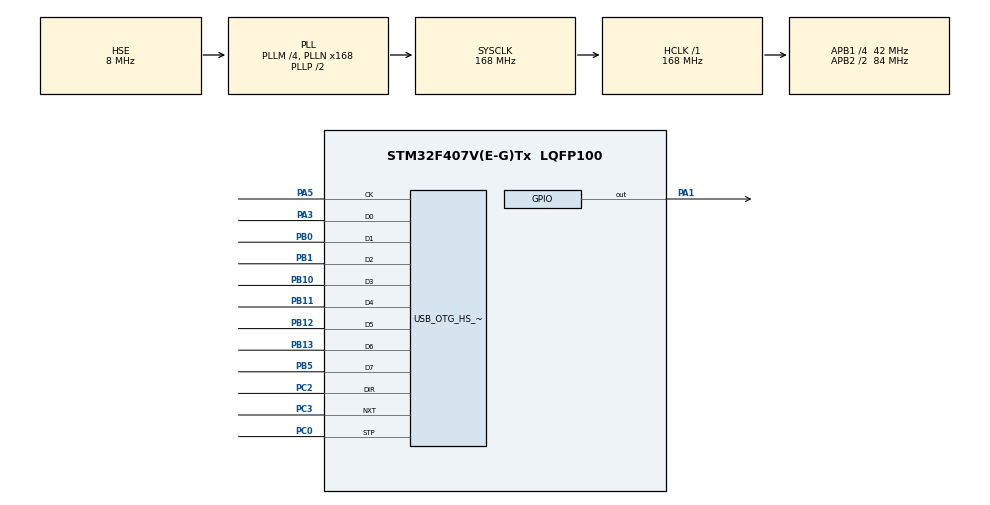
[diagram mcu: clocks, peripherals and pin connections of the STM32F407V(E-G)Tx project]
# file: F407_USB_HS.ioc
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FREERTOS.BinarySemaphores01=usbTxSemaphore,Dynamic,NULL
FREERTOS.INCLUDE_vTaskDelayUntil=1
FREERTOS.Tasks01=defaultTask,0,256,StartDefaultTask,Default,NULL,Dynamic,NULL,NULL;ledTask,-3,128,LEDTask,Default,NULL,Dynamic,NULL,NULL
FREERTOS.configTOTAL_HEAP_SIZE=10240
Mcu.Family=STM32F4
Mcu.Name=STM32F407V(E-G)Tx
Mcu.Package=LQFP100
NVIC.OTG_HS_IRQn=true\:5\:0\:false\:false\:true\:true\:false\:true\:true
NVIC.PriorityGroup=NVIC_PRIORITYGROUP_4
NVIC.TIM8_TRG_COM_TIM14_IRQn=true\:15\:0\:false\:false\:true\:false\:false\:true\:true
NVIC.TimeBase=TIM8_TRG_COM_TIM14_IRQn
NVIC.TimeBaseIP=TIM14
PA1.Signal=GPIO_Output
PA13.Mode=Serial_Wire
PA13.Signal=SYS_JTMS-SWDIO
PA14.Mode=Serial_Wire
PA14.Signal=SYS_JTCK-SWCLK
PA3.Mode=Device_HS
PA3.Signal=USB_OTG_HS_ULPI_D0
PA5.Mode=Device_HS
PA5.Signal=USB_OTG_HS_ULPI_CK
PB0.Mode=Device_HS
PB0.Signal=USB_OTG_HS_ULPI_D1
PB1.Mode=Device_HS
PB1.Signal=USB_OTG_HS_ULPI_D2
PB10.Mode=Device_HS
PB10.Signal=USB_OTG_HS_ULPI_D3
PB11.Mode=Device_HS
PB11.Signal=USB_OTG_HS_ULPI_D4
PB12.Mode=Device_HS
PB12.Signal=USB_OTG_HS_ULPI_D5
PB13.Mode=Device_HS
PB13.Signal=USB_OTG_HS_ULPI_D6
PB5.Mode=Device_HS
PB5.Signal=USB_OTG_HS_ULPI_D7
PC0.Mode=Device_HS
PC0.Signal=USB_OTG_HS_ULPI_STP
PC2.Mode=Device_HS
PC2.Signal=USB_OTG_HS_ULPI_DIR
PC3.Mode=Device_HS
PC3.Signal=USB_OTG_HS_ULPI_NXT
PH0-OSC_IN.Mode=HSE-External-Oscillator
PH0-OSC_IN.Signal=RCC_OSC_IN
PH1-OSC_OUT.Mode=HSE-External-Oscillator
PH1-OSC_OUT.Signal=RCC_OSC_OUT
ProjectManager.HeapSize=0x100
ProjectManager.StackSize=0x1000
ProjectManager.TargetToolchain=MDK-ARM V5.32
RCC.48MHZClocksFreq_Value=48000000
RCC.AHBFreq_Value=168000000
RCC.APB1CLKDivider=RCC_HCLK_DIV4
RCC.APB1Freq_Value=42000000
RCC.APB1TimFreq_Value=84000000
RCC.APB2CLKDivider=RCC_HCLK_DIV2
RCC.APB2Freq_Value=84000000
RCC.APB2TimFreq_Value=168000000
RCC.CortexFreq_Value=168000000
RCC.HCLKFreq_Value=168000000
RCC.HSE_VALUE=8000000
RCC.HSI_VALUE=16000000
RCC.LSE_VALUE=32768
RCC.PLLM=4
RCC.PLLN=168
RCC.PLLQ=7
RCC.PLLSourceVirtual=RCC_PLLSOURCE_HSE
RCC.SYSCLKFreq_VALUE=168000000
RCC.SYSCLKSource=RCC_SYSCLKSOURCE_PLLCLK
RCC.VCOOutputFreq_Value=336000000
USB_DEVICE.CLASS_NAME_HS=CDC
USB_DEVICE.VirtualMode-CDC_HS=Cdc
USB_DEVICE.VirtualModeHS=Cdc_HS
USB_OTG_HS.VirtualMode-Device_HS=Device_HS
VP_FREERTOS_VS_CMSIS_V1.Mode=CMSIS_V1
VP_SYS_VS_tim14.Mode=TIM14
VP_USB_DEVICE_VS_USB_DEVICE_CDC_HS.Mode=CDC_HS
board=custom

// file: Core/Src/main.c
/* USER CODE BEGIN Header */
/**
  ******************************************************************************
  * @file           : main.c
  * @brief          : Main program body
  ******************************************************************************
  * @attention
  *
  * Copyright (c) 2025 STMicroelectronics.
  * All rights reserved.
  *
  * This software is licensed under terms that can be found in the LICENSE file
  * in the root directory of this software component.
  * If no LICENSE file comes with this software, it is provided AS-IS.
  *
  ******************************************************************************
  */
/* USER CODE END Header */
#include "main.h"
#include "cmsis_os.h"
#include "usb_device.h"
#include "gpio.h"

void SystemClock_Config(void);
void MX_FREERTOS_Init(void);

int main(void)
{

  /* MCU Configuration--------------------------------------------------------*/

  /* Reset of all peripherals, Initializes the Flash interface and the Systick. */
  HAL_Init();

  /* Configure the system clock */
  SystemClock_Config();

  /* Initialize all configured peripherals */
  MX_GPIO_Init();

  /* Call init function for freertos objects (in freertos.c) */
  MX_FREERTOS_Init();

  /* Start scheduler */
  osKernelStart();

  /* We should never get here as control is now taken by the scheduler */
  /* Infinite loop */
  while (1)
  {

  }
}

void SystemClock_Config(void)
{
  RCC_OscInitTypeDef RCC_OscInitStruct = {0};
  RCC_ClkInitTypeDef RCC_ClkInitStruct = {0};

  /** Configure the main internal regulator output voltage
  */
  __HAL_RCC_PWR_CLK_ENABLE();
  __HAL_PWR_VOLTAGESCALING_CONFIG(PWR_REGULATOR_VOLTAGE_SCALE1);

  /** Initializes the RCC Oscillators according to the specified parameters
  * in the RCC_OscInitTypeDef structure.
  */
  RCC_OscInitStruct.OscillatorType = RCC_OSCILLATORTYPE_HSE;
  RCC_OscInitStruct.HSEState = RCC_HSE_ON;
  RCC_OscInitStruct.PLL.PLLState = RCC_PLL_ON;
  RCC_OscInitStruct.PLL.PLLSource = RCC_PLLSOURCE_HSE;
  RCC_OscInitStruct.PLL.PLLM = 4;
  RCC_OscInitStruct.PLL.PLLN = 168;
  RCC_OscInitStruct.PLL.PLLP = RCC_PLLP_DIV2;
  RCC_OscInitStruct.PLL.PLLQ = 7;
  if (HAL_RCC_OscConfig(&RCC_OscInitStruct) != HAL_OK)
  {
    Error_Handler();
  }

  /** Initializes the CPU, AHB and APB buses clocks
  */
  RCC_ClkInitStruct.ClockType = RCC_CLOCKTYPE_HCLK|RCC_CLOCKTYPE_SYSCLK
                              |RCC_CLOCKTYPE_PCLK1|RCC_CLOCKTYPE_PCLK2;
  RCC_ClkInitStruct.SYSCLKSource = RCC_SYSCLKSOURCE_PLLCLK;
  RCC_ClkInitStruct.AHBCLKDivider = RCC_SYSCLK_DIV1;
  RCC_ClkInitStruct.APB1CLKDivider = RCC_HCLK_DIV4;
  RCC_ClkInitStruct.APB2CLKDivider = RCC_HCLK_DIV2;

  if (HAL_RCC_ClockConfig(&RCC_ClkInitStruct, FLASH_LATENCY_5) != HAL_OK)
  {
    Error_Handler();
  }
}

void HAL_TIM_PeriodElapsedCallback(TIM_HandleTypeDef *htim)
{
  if (htim->Instance == TIM14) {
    HAL_IncTick();
  }
}

void Error_Handler(void)
{
  __disable_irq();
  while (1)
  {
  }
}

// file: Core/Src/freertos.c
/* USER CODE BEGIN Header */
/**
  ******************************************************************************
  * File Name          : freertos.c
  * Description        : Code for freertos applications
  ******************************************************************************
  * @attention
  *
  * Copyright (c) 2025 STMicroelectronics.
  * All rights reserved.
  *
  * This software is licensed under terms that can be found in the LICENSE file
  * in the root directory of this software component.
  * If no LICENSE file comes with this software, it is provided AS-IS.
  *
  ******************************************************************************
  */
/* USER CODE END Header */

#include "FreeRTOS.h"
#include "task.h"
#include "main.h"
#include "cmsis_os.h"

/* USER CODE BEGIN Includes */
#include "usbd_cdc_if.h"
/* USER CODE END Includes */

osThreadId defaultTaskHandle;
osThreadId ledTaskHandle;
osSemaphoreId usbTxSemaphoreHandle;

void StartDefaultTask(void const * argument);
void LEDTask(void const * argument);

extern void MX_USB_DEVICE_Init(void);
void MX_FREERTOS_Init(void); /* (MISRA C 2004 rule 8.1) */

/* GetIdleTaskMemory prototype (linked to static allocation support) */
void vApplicationGetIdleTaskMemory( StaticTask_t **ppxIdleTaskTCBBuffer, StackType_t **ppxIdleTaskStackBuffer, uint32_t *pulIdleTaskStackSize );

/* USER CODE BEGIN GET_IDLE_TASK_MEMORY */
static StaticTask_t xIdleTaskTCBBuffer;
static StackType_t xIdleStack[configMINIMAL_STACK_SIZE];

void vApplicationGetIdleTaskMemory( StaticTask_t **ppxIdleTaskTCBBuffer, StackType_t **ppxIdleTaskStackBuffer, uint32_t *pulIdleTaskStackSize )
{
  *ppxIdleTaskTCBBuffer = &xIdleTaskTCBBuffer;
  *ppxIdleTaskStackBuffer = &xIdleStack[0];
  *pulIdleTaskStackSize = configMINIMAL_STACK_SIZE;
  /* place for user code */
}
/* USER CODE END GET_IDLE_TASK_MEMORY */

void MX_FREERTOS_Init(void) {

  /* Create the semaphores(s) */
  /* definition and creation of usbTxSemaphore */
  osSemaphoreDef(usbTxSemaphore);
  usbTxSemaphoreHandle = osSemaphoreCreate(osSemaphore(usbTxSemaphore), 1);

  /* Create the thread(s) */
  /* definition and creation of defaultTask */
  osThreadDef(defaultTask, StartDefaultTask, osPriorityNormal, 0, 256);
  defaultTaskHandle = osThreadCreate(osThread(defaultTask), NULL);

  /* definition and creation of ledTask */
  osThreadDef(ledTask, LEDTask, osPriorityIdle, 0, 128);
  ledTaskHandle = osThreadCreate(osThread(ledTask), NULL);

}

/* USER CODE BEGIN Header_StartDefaultTask */
unsigned char test_buf[]="hello world\r\n";
unsigned char speed_test[10240];
/**
  * @brief  Function implementing the defaultTask thread.
  * @param  argument: Not used
  * @retval None
  */
/* USER CODE END Header_StartDefaultTask */
void StartDefaultTask(void const * argument)
{
  /* init code for USB_DEVICE */
  MX_USB_DEVICE_Init();
  /* USER CODE BEGIN StartDefaultTask */
	USBD_StatusTypeDef USB_TX_Status = USBD_OK;

	for(uint16_t i=0;i<10240;i++)
	{
		speed_test[i]=i;
	}
  /* Infinite loop */
	for(;;)
	{
//		do
//		{
//			USB_TX_Status = CDC_Transmit_HS(speed_test,sizeof(speed_test));
//		}
//		while(USB_TX_Status != USBD_OK);
//		osDelay(1);

		// 等待信号量（缓冲区空闲），超时时间设为永久等待（osWaitForever）
		if (osSemaphoreWait(usbTxSemaphoreHandle, osWaitForever) == osOK)
		{
			// 信号量获取成功（缓冲区空闲），立即发送
			USB_TX_Status = CDC_Transmit_HS(speed_test, sizeof(speed_test));

			// 理论上此时发送不会返回BUSY（因为信号量保证缓冲区空闲）
			// 若仍返回错误，可在这里处理（如重试）
			if (USB_TX_Status != USBD_OK)
			{
				// 发送失败，重新释放信号量（避免任务卡死）
				osSemaphoreRelease(usbTxSemaphoreHandle);
			}
		}
	}
  /* USER CODE END StartDefaultTask */
}

void LEDTask(void const * argument)
{
  /* USER CODE BEGIN LEDTask */
  /* Infinite loop */
	for(;;)
	{
		HAL_GPIO_TogglePin(GPIOA,GPIO_PIN_1);
		osDelay(100);
	}
  /* USER CODE END LEDTask */
}
